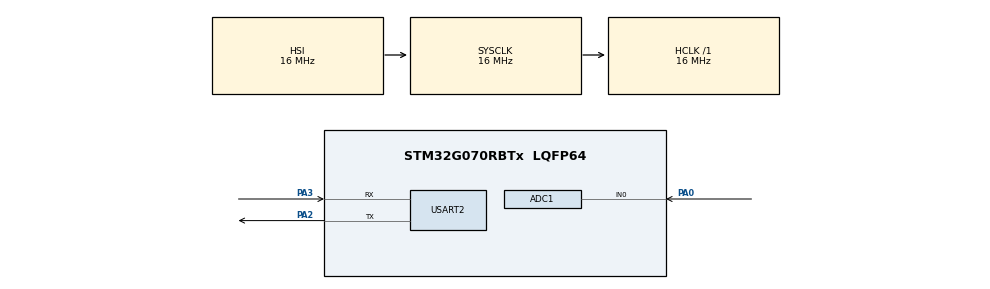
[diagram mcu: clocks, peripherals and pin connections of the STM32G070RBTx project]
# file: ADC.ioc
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ADC1.Channel-1\#ChannelRegularConversion=ADC_CHANNEL_0
ADC1.ContinuousConvMode=ENABLE
ADC1.NbrOfConversion=1
ADC1.NbrOfConversionFlag=1
ADC1.Rank-1\#ChannelRegularConversion=1
ADC1.SamplingTime-1\#ChannelRegularConversion=ADC_SAMPLINGTIME_COMMON_1
ADC1.SelectedChannel=ADC_CHANNEL_0
ADC1.master=1
Mcu.Family=STM32G0
Mcu.Name=STM32G070RBTx
Mcu.Package=LQFP64
NVIC.TIM3_IRQn=true\:3\:0\:false\:false\:true\:false\:true\:true
NVIC.TimeBase=TIM3_IRQn
NVIC.TimeBaseIP=TIM3
PA0.Mode=IN0
PA0.Signal=ADC1_IN0
PA13.Mode=Serial_Wire
PA13.Signal=SYS_SWDIO
PA14-BOOT0.Mode=Serial_Wire
PA14-BOOT0.Signal=SYS_SWCLK
PA2.Mode=Asynchronous
PA2.Signal=USART2_TX
PA3.Mode=Asynchronous
PA3.Signal=USART2_RX
PC14-OSC32_IN\ (PC14).Mode=LSE-External-Oscillator
PC14-OSC32_IN\ (PC14).Signal=RCC_OSC32_IN
PC15-OSC32_OUT\ (PC15).Mode=LSE-External-Oscillator
PC15-OSC32_OUT\ (PC15).Signal=RCC_OSC32_OUT
PF0-OSC_IN\ (PF0).Mode=HSE-External-Clock-Source
PF0-OSC_IN\ (PF0).Signal=RCC_OSC_IN
ProjectManager.HeapSize=0x200
ProjectManager.StackSize=0x400
ProjectManager.TargetToolchain=STM32CubeIDE
RCC.AHBFreq_Value=16000000
RCC.CortexFreq_Value=16000000
RCC.EXTERNAL_CLOCK_VALUE=12288000
RCC.HCLKFreq_Value=16000000
RCC.HSE_VALUE=8000000
RCC.HSI_VALUE=16000000
RCC.SYSCLKFreq_VALUE=16000000
RCC.VCOOutputFreq_Value=128000000
USART2.VirtualMode-Asynchronous=VM_ASYNC
VP_SYS_VS_tim3.Mode=TIM3
board=NUCLEO-G070RB

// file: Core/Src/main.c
/* USER CODE BEGIN Header */
/**
  ******************************************************************************
  * @file           : main.c
  * @brief          : Main program body
  ******************************************************************************
  * @attention
  *
  * Copyright (c) 2023 STMicroelectronics.
  * All rights reserved.
  *
  * This software is licensed under terms that can be found in the LICENSE file
  * in the root directory of this software component.
  * If no LICENSE file comes with this software, it is provided AS-IS.
  *
  ******************************************************************************
  */
/* USER CODE END Header */
#include "main.h"
#include <stdio.h>
#include <string.h>

/* USER CODE BEGIN Includes */
#include "FreeRTOS.h"
#include "task.h"

/* USER CODE END Includes */

ADC_HandleTypeDef hadc1;

UART_HandleTypeDef huart2;

/* USER CODE BEGIN PV */
uint32_t adc_res1;

/* USER CODE END PV */

void SystemClock_Config(void);
static void MX_GPIO_Init(void);
static void MX_USART2_UART_Init(void);
static void MX_ADC1_Init(void);
/* USER CODE BEGIN PFP */
static void task1(void *p);

/* USER CODE END PFP */

/* USER CODE BEGIN 0 */
static void task1(void *p)
{
	while(1)
	{
		char str[100];
		HAL_ADC_Start(&hadc1);
		if(HAL_ADC_PollForConversion(&hadc1, 100) ==HAL_OK)
		{
			adc_res1 = HAL_ADC_GetValue(&hadc1);
			sprintf(str, "The ADC Value is = %d\r\n", adc_res1);
			HAL_UART_Transmit(&huart2, (uint8_t *) str, strlen(str), HAL_MAX_DELAY);
		}
	}
}

/* USER CODE END 0 */

int main(void)
{
  /* USER CODE BEGIN 1 */
	TaskHandle_t t1;

  /* USER CODE END 1 */

  /* MCU Configuration--------------------------------------------------------*/

  /* Reset of all peripherals, Initializes the Flash interface and the Systick. */
  HAL_Init();

  /* Configure the system clock */
  SystemClock_Config();

  /* Initialize all configured peripherals */
  MX_GPIO_Init();
  MX_USART2_UART_Init();
  MX_ADC1_Init();
  /* USER CODE BEGIN 2 */
  xTaskCreate(task1,"t1", 200, NULL, 2, &t1);
  vTaskStartScheduler();

  /* USER CODE END 2 */

  /* Infinite loop */
  while (1)
  {

  }
}

void SystemClock_Config(void)
{
  RCC_OscInitTypeDef RCC_OscInitStruct = {0};
  RCC_ClkInitTypeDef RCC_ClkInitStruct = {0};

  /** Configure the main internal regulator output voltage
  */
  HAL_PWREx_ControlVoltageScaling(PWR_REGULATOR_VOLTAGE_SCALE1);

  /** Initializes the RCC Oscillators according to the specified parameters
  * in the RCC_OscInitTypeDef structure.
  */
  RCC_OscInitStruct.OscillatorType = RCC_OSCILLATORTYPE_HSI;
  RCC_OscInitStruct.HSIState = RCC_HSI_ON;
  RCC_OscInitStruct.HSIDiv = RCC_HSI_DIV1;
  RCC_OscInitStruct.HSICalibrationValue = RCC_HSICALIBRATION_DEFAULT;
  RCC_OscInitStruct.PLL.PLLState = RCC_PLL_NONE;
  if (HAL_RCC_OscConfig(&RCC_OscInitStruct) != HAL_OK)
  {
    Error_Handler();
  }

  /** Initializes the CPU, AHB and APB buses clocks
  */
  RCC_ClkInitStruct.ClockType = RCC_CLOCKTYPE_HCLK|RCC_CLOCKTYPE_SYSCLK
                              |RCC_CLOCKTYPE_PCLK1;
  RCC_ClkInitStruct.SYSCLKSource = RCC_SYSCLKSOURCE_HSI;
  RCC_ClkInitStruct.AHBCLKDivider = RCC_SYSCLK_DIV1;
  RCC_ClkInitStruct.APB1CLKDivider = RCC_HCLK_DIV1;

  if (HAL_RCC_ClockConfig(&RCC_ClkInitStruct, FLASH_LATENCY_0) != HAL_OK)
  {
    Error_Handler();
  }
}

static void MX_ADC1_Init(void)
{

  ADC_ChannelConfTypeDef sConfig = {0};

  /** Configure the global features of the ADC (Clock, Resolution, Data Alignment and number of conversion)
  */
  hadc1.Instance = ADC1;
  hadc1.Init.ClockPrescaler = ADC_CLOCK_SYNC_PCLK_DIV2;
  hadc1.Init.Resolution = ADC_RESOLUTION_12B;
  hadc1.Init.DataAlign = ADC_DATAALIGN_RIGHT;
  hadc1.Init.ScanConvMode = ADC_SCAN_DISABLE;
  hadc1.Init.EOCSelection = ADC_EOC_SINGLE_CONV;
  hadc1.Init.LowPowerAutoWait = DISABLE;
  hadc1.Init.LowPowerAutoPowerOff = DISABLE;
  hadc1.Init.ContinuousConvMode = ENABLE;
  hadc1.Init.NbrOfConversion = 1;
  hadc1.Init.ExternalTrigConv = ADC_SOFTWARE_START;
  hadc1.Init.ExternalTrigConvEdge = ADC_EXTERNALTRIGCONVEDGE_NONE;
  hadc1.Init.DMAContinuousRequests = DISABLE;
  hadc1.Init.Overrun = ADC_OVR_DATA_PRESERVED;
  hadc1.Init.SamplingTimeCommon1 = ADC_SAMPLETIME_1CYCLE_5;
  hadc1.Init.SamplingTimeCommon2 = ADC_SAMPLETIME_1CYCLE_5;
  hadc1.Init.OversamplingMode = DISABLE;
  hadc1.Init.TriggerFrequencyMode = ADC_TRIGGER_FREQ_HIGH;
  if (HAL_ADC_Init(&hadc1) != HAL_OK)
  {
    Error_Handler();
  }

  /** Configure Regular Channel
  */
  sConfig.Channel = ADC_CHANNEL_0;
  sConfig.Rank = ADC_REGULAR_RANK_1;
  sConfig.SamplingTime = ADC_SAMPLINGTIME_COMMON_1;
  if (HAL_ADC_ConfigChannel(&hadc1, &sConfig) != HAL_OK)
  {
    Error_Handler();
  }

}

static void MX_USART2_UART_Init(void)
{

  huart2.Instance = USART2;
  huart2.Init.BaudRate = 115200;
  huart2.Init.WordLength = UART_WORDLENGTH_8B;
  huart2.Init.StopBits = UART_STOPBITS_1;
  huart2.Init.Parity = UART_PARITY_NONE;
  huart2.Init.Mode = UART_MODE_TX_RX;
  huart2.Init.HwFlowCtl = UART_HWCONTROL_NONE;
  huart2.Init.OverSampling = UART_OVERSAMPLING_16;
  huart2.Init.OneBitSampling = UART_ONE_BIT_SAMPLE_DISABLE;
  huart2.Init.ClockPrescaler = UART_PRESCALER_DIV1;
  huart2.AdvancedInit.AdvFeatureInit = UART_ADVFEATURE_NO_INIT;
  if (HAL_UART_Init(&huart2) != HAL_OK)
  {
    Error_Handler();
  }
  if (HAL_UARTEx_SetTxFifoThreshold(&huart2, UART_TXFIFO_THRESHOLD_1_8) != HAL_OK)
  {
    Error_Handler();
  }
  if (HAL_UARTEx_SetRxFifoThreshold(&huart2, UART_RXFIFO_THRESHOLD_1_8) != HAL_OK)
  {
    Error_Handler();
  }
  if (HAL_UARTEx_DisableFifoMode(&huart2) != HAL_OK)
  {
    Error_Handler();
  }

}

static void MX_GPIO_Init(void)
{

  /* GPIO Ports Clock Enable */
  __HAL_RCC_GPIOC_CLK_ENABLE();
  __HAL_RCC_GPIOF_CLK_ENABLE();
  __HAL_RCC_GPIOA_CLK_ENABLE();

}

void HAL_TIM_PeriodElapsedCallback(TIM_HandleTypeDef *htim)
{
  if (htim->Instance == TIM3) {
    HAL_IncTick();
  }
}

void Error_Handler(void)
{
  __disable_irq();
  while (1)
  {
  }
}
